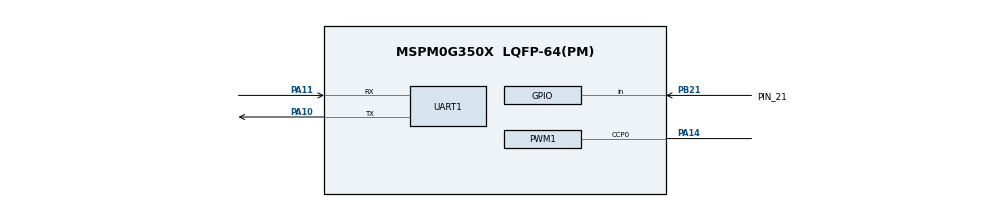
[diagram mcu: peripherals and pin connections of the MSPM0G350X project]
/**
 * @cliArgs --device "MSPM0G350X" --part "Default" --package "LQFP-64(PM)" --product "mspm0_sdk@2.10.00.04"
 * @versions {"tool":"1.26.2+4477"}
 */

/**
 * Import the modules used in this configuration.
 */
const GPIO    = scripting.addModule("/ti/driverlib/GPIO", {}, false);
const GPIO1   = GPIO.addInstance();
const GPIO2   = GPIO.addInstance();
const GPIO3   = GPIO.addInstance();
const GPIO4   = GPIO.addInstance();
const PWM     = scripting.addModule("/ti/driverlib/PWM", {}, false);
const PWM1    = PWM.addInstance();
const SYSCTL  = scripting.addModule("/ti/driverlib/SYSCTL");
const SYSTICK = scripting.addModule("/ti/driverlib/SYSTICK");
const UART    = scripting.addModule("/ti/driverlib/UART", {}, false);
const UART1   = UART.addInstance();

/**
 * Write custom configuration values to the imported modules.
 */
GPIO1.port                               = "PORTB";
GPIO1.$name                              = "LED";
GPIO1.associatedPins[0].$name            = "PIN_14";
GPIO1.associatedPins[0].internalResistor = "PULL_DOWN";
GPIO1.associatedPins[0].assignedPin      = "14";

const Board = scripting.addModule("/ti/driverlib/Board", {}, false);

GPIO2.$name                              = "KEY";
GPIO2.port                               = "PORTB";
GPIO2.associatedPins[0].$name            = "PIN_21";
GPIO2.associatedPins[0].direction        = "INPUT";
GPIO2.associatedPins[0].assignedPin      = "21";
GPIO2.associatedPins[0].internalResistor = "PULL_UP";
GPIO2.associatedPins[0].pin.$assign      = "PB21";

GPIO3.$name                         = "OLED_SCL";
GPIO3.port                          = "PORTA";
GPIO3.associatedPins[0].$name       = "PIN_29";
GPIO3.associatedPins[0].assignedPin = "29";

GPIO4.$name                         = "OLED_SDA";
GPIO4.port                          = "PORTA";
GPIO4.associatedPins[0].$name       = "PIN_30";
GPIO4.associatedPins[0].assignedPin = "30";

PWM1.$name                              = "PWM_14";
PWM1.timerCount                         = 32000;
PWM1.ccIndex                            = [0];
PWM1.pwmMode                            = "CENTER_ALIGN";
PWM1.timerStartTimer                    = true;
PWM1.PWM_CHANNEL_0.$name                = "ti_driverlib_pwm_PWMTimerCC0";
PWM1.PWM_CHANNEL_0.dutyCycle            = 50;
PWM1.ccp0PinConfig.$name                = "ti_driverlib_gpio_GPIOPinGeneric0";
PWM1.ccp0PinConfig.direction            = scripting.forceWrite("OUTPUT");
PWM1.ccp0PinConfig.hideOutputInversion  = scripting.forceWrite(false);
PWM1.ccp0PinConfig.onlyInternalResistor = scripting.forceWrite(false);
PWM1.ccp0PinConfig.passedPeripheralType = scripting.forceWrite("Digital");
PWM1.peripheral.$assign                 = "TIMG12";
PWM1.peripheral.ccp0Pin.$assign         = "PA14";

SYSCTL.forceDefaultClkConfig = true;

SYSTICK.periodEnable      = true;
SYSTICK.period            = 32000;
SYSTICK.interruptEnable   = true;
SYSTICK.interruptPriority = "1";
SYSTICK.systickEnable     = true;

UART1.$name                    = "UART_0";
UART1.enabledInterrupts        = ["RX"];
UART1.peripheral.rxPin.$assign = "PA11";
UART1.peripheral.txPin.$assign = "PA10";
UART1.txPinConfig.$name        = "ti_driverlib_gpio_GPIOPinGeneric1";
UART1.rxPinConfig.$name        = "ti_driverlib_gpio_GPIOPinGeneric2";

/**
 * Pinmux solution for unlocked pins/peripherals. This ensures that minor changes to the automatic solver in a future
 * version of the tool will not impact the pinmux you originally saw.  These lines can be completely deleted in order to
 * re-solve from scratch.
 */
GPIO1.associatedPins[0].pin.$suggestSolution = "PB14";
Board.peripheral.$suggestSolution            = "DEBUGSS";
Board.peripheral.swclkPin.$suggestSolution   = "PA20";
Board.peripheral.swdioPin.$suggestSolution   = "PA19";
GPIO3.associatedPins[0].pin.$suggestSolution = "PA29";
GPIO4.associatedPins[0].pin.$suggestSolution = "PA30";
SYSCTL.peripheral.$suggestSolution           = "SYSCTL";
UART1.peripheral.$suggestSolution            = "UART0";
